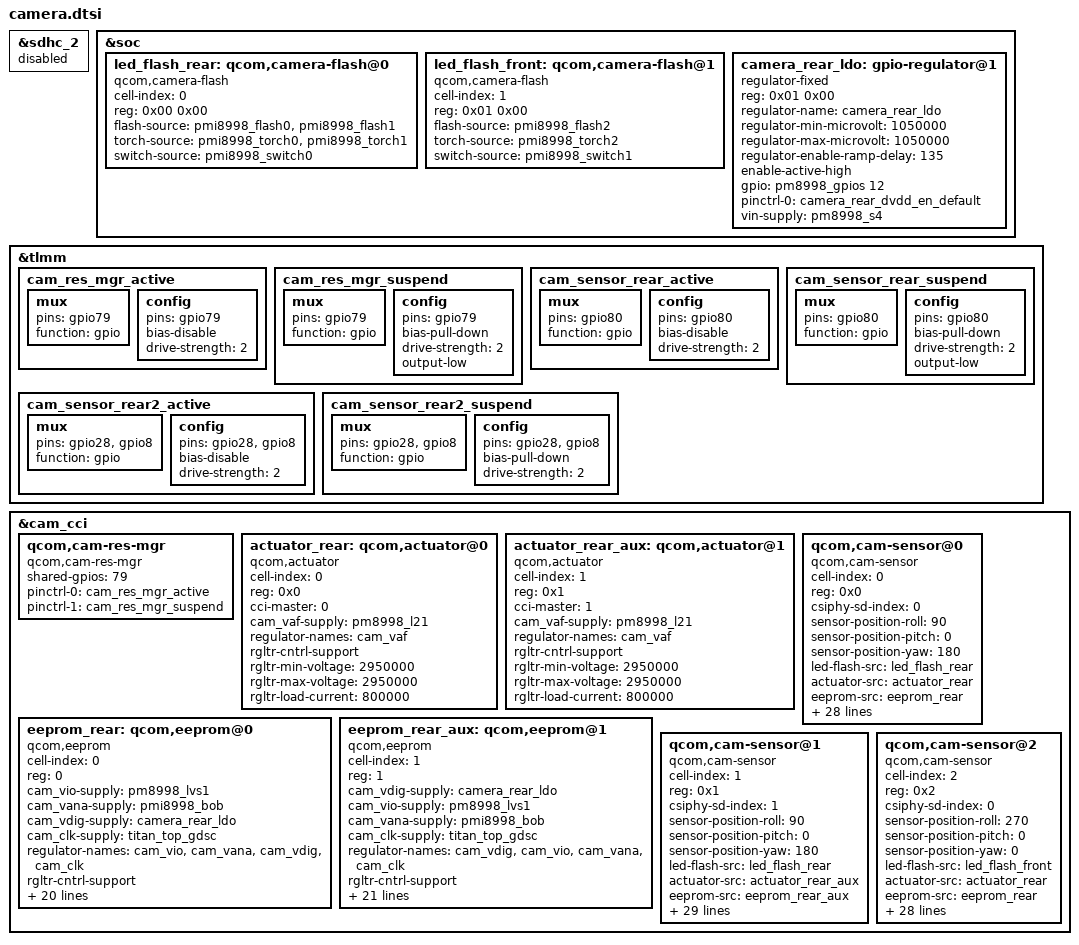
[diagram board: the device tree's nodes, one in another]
/*
 * Copyright (c) 2015-2016, The Linux Foundation. All rights reserved.
 *
 * This program is free software; you can redistribute it and/or modify
 * it under the terms of the GNU General Public License version 2 and
 * only version 2 as published by the Free Software Foundation.
 *
 * This program is distributed in the hope that it will be useful,
 * but WITHOUT ANY WARRANTY; without even the implied warranty of
 * MERCHANTABILITY or FITNESS FOR A PARTICULAR PURPOSE.  See the
 * GNU General Public License for more details.
 */




&sdhc_2 {
	status = "disabled";
};
 &soc {

	led_flash_rear: qcom,camera-flash@0 {
		cell-index = <0>;
		reg = <0x00 0x00>;
		compatible = "qcom,camera-flash";
		flash-source = <&pmi8998_flash0 &pmi8998_flash1>;
		torch-source = <&pmi8998_torch0 &pmi8998_torch1>;
		switch-source = <&pmi8998_switch0>;
		status = "ok";
	};
	
	led_flash_front: qcom,camera-flash@1 {
		cell-index = <1>;
		reg = <0x01 0x00>;
		compatible = "qcom,camera-flash";
		flash-source = <&pmi8998_flash2>;
		torch-source = <&pmi8998_torch2>;
		switch-source = <&pmi8998_switch1>;
		status = "ok";
	};

	camera_rear_ldo: gpio-regulator@1 {
		compatible = "regulator-fixed";
		reg = <0x01 0x00>;
		regulator-name = "camera_rear_ldo";
		regulator-min-microvolt = <1050000>;
		regulator-max-microvolt = <1050000>;
		regulator-enable-ramp-delay = <135>;
		enable-active-high;
		gpio = <&pm8998_gpios 12 0>;
		pinctrl-names = "default";
		pinctrl-0 = <&camera_rear_dvdd_en_default>;
		vin-supply = <&pm8998_s4>;
	};
	/*camera_aux_ldo: gpio-regulator@2 {
		compatible = "regulator-fixed";
		reg = <0x02 0x00>;
		regulator-name = "camera_aux_ldo";
		regulator-min-microvolt = <1050000>;
		regulator-max-microvolt = <1050000>;
		regulator-enable-ramp-delay = <100>;
		enable-active-high;
		gpio = <&tlmm 8 0>;
		vin-supply = <&pm8998_s4>;
	};*/
};

&tlmm {
	/delete-node/ cam_sensor_rear2_active;
	/delete-node/ cam_sensor_rear2_suspend;	
	/delete-node/ cam_sensor_rear_active;
	/delete-node/ cam_sensor_rear_suspend;
	/delete-node/ cam_res_mgr_active;
	/delete-node/ cam_res_mgr_suspend;

	cam_res_mgr_active: cam_res_mgr_active {
		/* AVDD_LDO*/
		mux {
			pins = "gpio79";
			function = "gpio";
		};

		config {
			pins = "gpio79";
			bias-disable; /* No PULL */
			drive-strength = <2>; /* 2 MA */
		};
	};

	cam_res_mgr_suspend: cam_res_mgr_suspend {
		/* AVDD_LDO */
		mux {
			pins = "gpio79";
			function = "gpio";
		};

		config {
			pins = "gpio79";
			bias-pull-down; /* PULL DOWN */
			drive-strength = <2>; /* 2 MA */
			output-low;
		};
	};

	cam_sensor_rear_active: cam_sensor_rear_active {
		/* RESET */
		mux {
			pins = "gpio80";
			function = "gpio";
		};

		config {
			pins = "gpio80";
			bias-disable; /* No PULL */
			drive-strength = <2>; /* 2 MA */
		};
	};

	cam_sensor_rear_suspend: cam_sensor_rear_suspend {
		/* RESET */
		mux {
			pins = "gpio80";
			function = "gpio";
		};

		config {
			pins = "gpio80";
			bias-pull-down; /* PULL DOWN */
			drive-strength = <2>; /* 2 MA */
			output-low;
		};
	};

	cam_sensor_rear2_active: cam_sensor_rear2_active {
		/* RESET, STANDBY */
		mux {
			pins = "gpio28","gpio8";
			function = "gpio";
		};
		config {
			pins = "gpio28","gpio8";
			bias-disable; /* No PULL */
			drive-strength = <2>; /* 2 MA */
		};
	};
	cam_sensor_rear2_suspend: cam_sensor_rear2_suspend {
		/* RESET, STANDBY */
		mux {
			pins = "gpio28","gpio8";
			function = "gpio";
		};
		config {
			pins = "gpio28","gpio8";
			bias-pull-down; /* PULL DOWN */
			drive-strength = <2>; /* 2 MA */
		};
	};	
};

&cam_cci {

	qcom,cam-res-mgr {
		compatible = "qcom,cam-res-mgr";
		status = "ok";
		shared-gpios = <79>;
		pinctrl-names = "cam_res_mgr_default", "cam_res_mgr_suspend";
		pinctrl-0 = <&cam_res_mgr_active>;
		pinctrl-1 = <&cam_res_mgr_suspend>;
	};

	actuator_rear: qcom,actuator@0 {
		cell-index = <0>;
		reg = <0x0>;
		compatible = "qcom,actuator";
		cci-master = <0>;
		cam_vaf-supply = <&pm8998_l21>;
		regulator-names = "cam_vaf";
		rgltr-cntrl-support;
		rgltr-min-voltage = <2950000>;
		rgltr-max-voltage = <2950000>;
		rgltr-load-current = <800000>;		
	};
	actuator_rear_aux: qcom,actuator@1 {
		cell-index = <1>;
		reg = <0x1>;
		compatible = "qcom,actuator";
		cci-master = <1>;
		cam_vaf-supply = <&pm8998_l21>;
		regulator-names = "cam_vaf";
		rgltr-cntrl-support;
		rgltr-min-voltage = <2950000>;
		rgltr-max-voltage = <2950000>;
		rgltr-load-current = <800000>;
	};
	eeprom_rear: qcom,eeprom@0 {
		cell-index = <0>;
		reg = <0>;
		compatible = "qcom,eeprom";
		cam_vio-supply = <&pm8998_lvs1>;
		cam_vana-supply = <&pmi8998_bob>;
		cam_vdig-supply = <&camera_rear_ldo>;
		cam_clk-supply = <&titan_top_gdsc>;
		regulator-names = "cam_vio", "cam_vana", "cam_vdig",
			"cam_clk";
		rgltr-cntrl-support;
		rgltr-min-voltage = <0 3312000 1050000 0>;
		rgltr-max-voltage = <0 3312000 1050000 0>;
		rgltr-load-current = <0 80000 105000 0>;
		gpio-no-mux = <0>;
		pinctrl-names = "cam_default", "cam_suspend";
		pinctrl-0 = <&cam_sensor_mclk0_active
				&cam_sensor_rear_active>;
		pinctrl-1 = <&cam_sensor_mclk0_suspend
				&cam_sensor_rear_suspend>;
		gpios = <&tlmm 13 0>,
			<&tlmm 80 0>,
			<&tlmm 79 0>;
		gpio-reset = <1>;
		gpio-vana = <2>;
		gpio-req-tbl-num = <0 1 2>;
		gpio-req-tbl-flags = <1 0 0>;
		gpio-req-tbl-label = "CAMIF_MCLK0",
					"CAM_RESET0",
					"CAM_VANA0";
		sensor-mode = <0>;
		cci-master = <0>;
		status = "ok";
		clocks = <&clock_camcc CAM_CC_MCLK0_CLK>;
		clock-names = "cam_clk";
		clock-cntl-level = "turbo";
		clock-rates = <24000000>;
	};

	eeprom_rear_aux: qcom,eeprom@1 {
		cell-index = <1>;
		reg = <1>;
		compatible = "qcom,eeprom";
		cam_vdig-supply = <&camera_rear_ldo>;
		cam_vio-supply = <&pm8998_lvs1>;
		cam_vana-supply = <&pmi8998_bob>;
		cam_clk-supply = <&titan_top_gdsc>;
		regulator-names = "cam_vdig", "cam_vio", "cam_vana",
			"cam_clk";
		rgltr-cntrl-support;
		rgltr-min-voltage = <1050000 0 3312000 0>;
		rgltr-max-voltage = <1050000 0 3312000 0>;
		rgltr-load-current = <105000 0 80000 0>;
		gpio-no-mux = <0>;
		pinctrl-names = "cam_default", "cam_suspend";
		pinctrl-0 = <&cam_sensor_mclk1_active
				&cam_sensor_rear2_active>;
		pinctrl-1 = <&cam_sensor_mclk1_suspend
				&cam_sensor_rear2_suspend>;
		gpios = <&tlmm 14 0>,
			<&tlmm 28 0>,
			<&tlmm 79 0>,
			<&tlmm 8 0>;
		gpio-reset = <1>;
		gpio-vana = <2>;
		gpio-standby = <3>;
		gpio-req-tbl-num = <0 1 2 3>;
		gpio-req-tbl-flags = <1 0 0 0>;
		gpio-req-tbl-label = "CAMIF_MCLK1",
					"CAM_RESET1",
					"CAM_VANA1",
					"CAM_STANDBY1";
		sensor-mode = <0>;
		cci-master = <1>;
		status = "ok";
		clocks = <&clock_camcc CAM_CC_MCLK1_CLK>;
		clock-names = "cam_clk";
		clock-cntl-level = "turbo";
		clock-rates = <24000000>;
	};

	qcom,cam-sensor@0 {
		cell-index = <0>;
		compatible = "qcom,cam-sensor";
		reg = <0x0>;
		csiphy-sd-index = <0>;
		sensor-position-roll = <90>;
		sensor-position-pitch = <0>;
		sensor-position-yaw = <180>;
		led-flash-src = <&led_flash_rear>;
		actuator-src = <&actuator_rear>;
		//ois-src = <&ois_rear>;
		eeprom-src = <&eeprom_rear>;
		cam_vio-supply = <&pm8998_lvs1>;
		cam_vana-supply = <&pmi8998_bob>;
		cam_vdig-supply = <&camera_rear_ldo>;
		cam_clk-supply = <&titan_top_gdsc>;
		cam_vaf-supply = <&pm8998_l21>;
		regulator-names = "cam_vio", "cam_vana", "cam_vdig","cam_vaf",
			"cam_clk";
		rgltr-cntrl-support;
		rgltr-min-voltage = <0 3312000 1050000 2950000 0>;
		rgltr-max-voltage = <0 3312000 1050000 2950000 0>;
		rgltr-load-current = <0 80000 105000 80000 0>;
		gpio-no-mux = <0>;
		pinctrl-names = "cam_default", "cam_suspend";
		pinctrl-0 = <&cam_sensor_mclk0_active
				&cam_sensor_rear_active>;
		pinctrl-1 = <&cam_sensor_mclk0_suspend
				&cam_sensor_rear_suspend>;
		gpios = <&tlmm 13 0>,
			<&tlmm 80 0>,
			<&tlmm 79 0>;
		gpio-reset = <1>;
		gpio-vana = <2>;
		gpio-req-tbl-num = <0 1 2>;
		gpio-req-tbl-flags = <1 0 0>;
		gpio-req-tbl-label = "CAMIF_MCLK0",
					"CAM_RESET0",
					"CAM_VANA0";
		sensor-mode = <0>;
		cci-master = <0>;
		status = "ok";
		clocks = <&clock_camcc CAM_CC_MCLK0_CLK>;
		clock-names = "cam_clk";
		clock-cntl-level = "turbo";
		clock-rates = <24000000>;
	};
	qcom,cam-sensor@1 {
		cell-index = <1>;
		compatible = "qcom,cam-sensor";
		reg = <0x1>;
		csiphy-sd-index = <1>;
		sensor-position-roll = <90>;
		sensor-position-pitch = <0>;
		sensor-position-yaw = <180>;
		led-flash-src = <&led_flash_rear>;
		actuator-src = <&actuator_rear_aux>;
		eeprom-src = <&eeprom_rear_aux>;
		cam_vdig-supply = <&camera_rear_ldo>;
		cam_vio-supply = <&pm8998_lvs1>;
		cam_vana-supply = <&pmi8998_bob>;
		cam_clk-supply = <&titan_top_gdsc>;
		cam_vaf-supply = <&pm8998_l21>;
		regulator-names = "cam_vdig", "cam_vio", "cam_vana","cam_vaf",
			"cam_clk";
		rgltr-cntrl-support;
		rgltr-min-voltage = <1050000 0 3312000 2950000 0>;
		rgltr-max-voltage = <1050000 0 3312000 2950000 0>;
		rgltr-load-current = <105000 0 80000 80000 0>;
		gpio-no-mux = <0>;
		pinctrl-names = "cam_default", "cam_suspend";
		pinctrl-0 = <&cam_sensor_mclk1_active
				&cam_sensor_rear2_active>;
		pinctrl-1 = <&cam_sensor_mclk1_suspend
				&cam_sensor_rear2_suspend>;
		gpios = <&tlmm 14 0>,
			<&tlmm 28 0>,
			<&tlmm 79 0>,
			<&tlmm 8 0>;
		gpio-reset = <1>;
		gpio-vana = <2>;
		gpio-standby = <3>;
		gpio-req-tbl-num = <0 1 2 3>;
		gpio-req-tbl-flags = <1 0 0 0>;
		gpio-req-tbl-label = "CAMIF_MCLK1",
					"CAM_RESET1",
					"CAM_VANA1",
					"CAM_STANDBY1";
		sensor-mode = <0>;
		cci-master = <1>;
		status = "ok";
		clocks = <&clock_camcc CAM_CC_MCLK1_CLK>;
		clock-names = "cam_clk";
		clock-cntl-level = "turbo";
		clock-rates = <24000000>;
	};
	qcom,cam-sensor@2 {
		cell-index = <2>;
		compatible = "qcom,cam-sensor";
		reg = <0x2>;
		csiphy-sd-index = <0>;
		sensor-position-roll = <270>;
		sensor-position-pitch = <0>;
		sensor-position-yaw = <0>;
		led-flash-src = <&led_flash_front>;
		actuator-src = <&actuator_rear>;
		//ois-src = <&ois_rear>;
		eeprom-src = <&eeprom_rear>;
		cam_vio-supply = <&pm8998_lvs1>;
		cam_vana-supply = <&pmi8998_bob>;
		cam_vdig-supply = <&camera_rear_ldo>;
		cam_clk-supply = <&titan_top_gdsc>;
		cam_vaf-supply = <&pm8998_l21>;
		regulator-names = "cam_vio", "cam_vana", "cam_vdig","cam_vaf",
			"cam_clk";
		rgltr-cntrl-support;
		rgltr-min-voltage = <0 3312000 1050000 2950000 0>;
		rgltr-max-voltage = <0 3312000 1050000 2950000 0>;
		rgltr-load-current = <0 80000 105000 80000 0>;
		gpio-no-mux = <0>;
		pinctrl-names = "cam_default", "cam_suspend";
		pinctrl-0 = <&cam_sensor_mclk0_active
				&cam_sensor_rear_active>;
		pinctrl-1 = <&cam_sensor_mclk0_suspend
				&cam_sensor_rear_suspend>;
		gpios = <&tlmm 13 0>,
			<&tlmm 80 0>,
			<&tlmm 79 0>;
		gpio-reset = <1>;
		gpio-vana = <2>;
		gpio-req-tbl-num = <0 1 2>;
		gpio-req-tbl-flags = <1 0 0>;
		gpio-req-tbl-label = "CAMIF_MCLK0",
					"CAM_RESET0",
					"CAM_VANA0";
		sensor-mode = <0>;
		cci-master = <0>;
		status = "ok";
		clocks = <&clock_camcc CAM_CC_MCLK0_CLK>;
		clock-names = "cam_clk";
		clock-cntl-level = "turbo";
		clock-rates = <24000000>;
	};
};
